AUTOSAR XML (schema 4-3-1)
package /Component
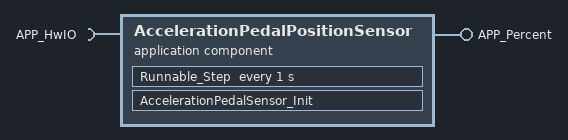
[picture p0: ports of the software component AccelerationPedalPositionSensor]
  application sw component type AccelerationPedalPositionSensor
    provide port APP_Percent: nonqueued-sender-com-spec{data-element=Value_2, init-value=0}, provided-interface=APP_Percent
    require port APP_HwIO: nonqueued-receiver-com-spec{data-element=Value_1, init-value=0}, required-interface=APP_HwIO
    behavior test_IB: handle-termination-and-restart=NO-SUPPORT
      timing event Event_Runnable_Step: start-on-event=Runnable_Step, period=1
      runnable AccelerationPedalSensor_Init
      runnable Runnable_Step
        data-read-access:
          access IN_APP_HwIO_Value_1: accessed-variable=APP_HwIO.Value_1
        data-write-access:
          access OUT_APP_Percent_Value_2: accessed-variable=APP_Percent.Value_2
      per-instance-parameters:
        parameter data prototype SetpointPercent_LkupTbl: category=CURVE, sw-calibration-access=READ-WRITE, type=Appl_SetpointPercent_LkupTbl, init-value=constant-reference={short-label=SetpointPercent_LkupTbl, constant=SetpointPercent_LkupTbl}
